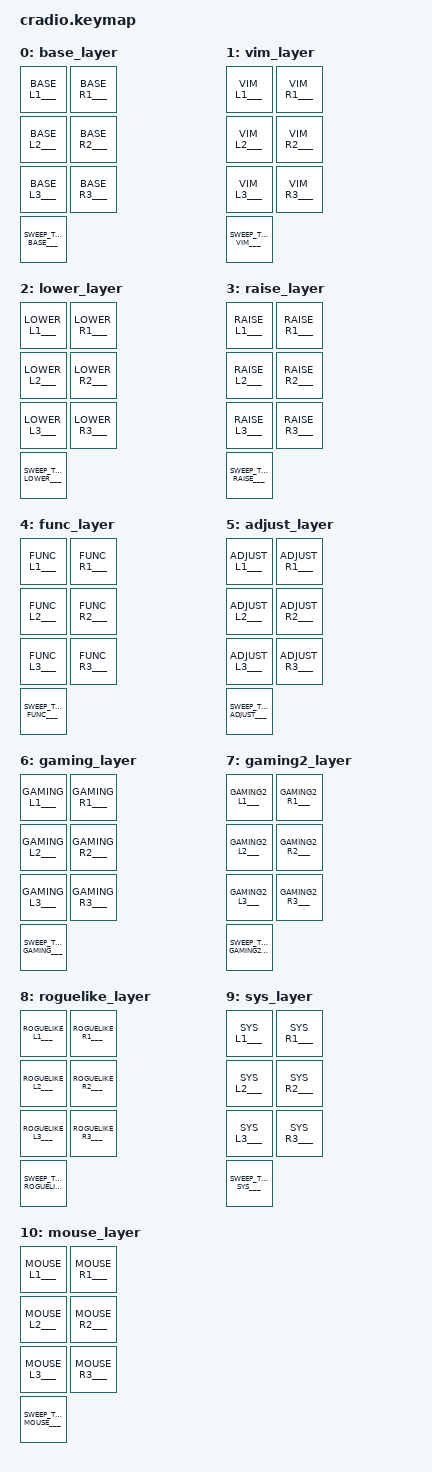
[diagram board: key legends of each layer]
// clang-format off
#include <behaviors.dtsi>
#include <dt-bindings/zmk/keys.h>
#include <dt-bindings/zmk/mouse.h>
#include "behaviors.dtsi" // before wrappers because .dtsi are fucking dumb
#include "combos.dtsi" // Shared combo definitions

/*                              34 KEY MATRIX / LAYOUT MAPPING
  ╭────────────────────┬────────────────────╮ ╭─────────────────────┬─────────────────────╮
  │  0   1   2   3   4 │  5   6   7   8   9 │ │ LT4 LT3 LT2 LT1 LT0 │ RT0 RT1 RT2 RT3 RT4 │
  │ 10  11  12  13  14 │ 15  16  17  18  19 │ │ LM4 LM3 LM2 LM1 LM0 │ RM0 RM1 RM2 RM3 RM4 │
  │ 20  21  22  23  24 │ 25  26  27  28  29 │ │ LB4 LB3 LB2 LB1 LB0 │ RB0 RB1 RB2 RB3 RB4 │
  ╰───────────╮ 30  31 │ 32  33 ╭───────────╯ ╰───────────╮ LH1 LH0 │ RH0 RH1 ╭───────────╯
              ╰────────┴────────╯                         ╰─────────┴─────────╯             */
/*            little cheater map just to fix brain farts
  ╭────────────────────┬────────────────────╮
  │  0   1   2   3   4 │  5   6   7   8   9 │
     Q   W   E   R   T    Y   U   I   O   P
  │ 10  11  12  13  14 │ 15  16  17  18  19 │
     A   S   D   F   G    H   J   K   L   ;
  │ 20  21  22  23  24 │ 25  26  27  28  29 │
     Z   X   C   V   B    N   M   ,   .   /
  ╰───────────╮ 30  31 │ 32  33 ╭───────────╯
              Bspc Space Enter Tab
              ╰────────┴────────╯ */
/ {
    combos {
        // basic functions we love
        combo_hj_caps_word {
            key-positions = <15 16>;
        };
        combo_yh_num_word {
            key-positions = <15 5>;
        };
        combo_jk_esc {
            key-positions = <16 17>;
        };
        combo_lscln_ent {
            key-positions = <18 19>;
        };
        combo_fg_tab {
            key-positions = <13 14>;
        };
        combo_cv_minus {
            key-positions = <22 23>;
        };
        combo_zx_del {
            key-positions = <20 21>;
        };
        combo_dc_assign {
            key-positions = <12 22>;
        };
        combo_gb_leader {
            key-positions = <14 24>;  // G + B
        };
        combo_as_bspc {
            key-positions = <10 11>;
        };
        combo_ui_equal {
            key-positions = <6 7>;  // U + I
        };
        combo_df_underscore {
            key-positions = <12 13>;
        };
        combo_vb_space {
            key-positions = <23 24>;  // V + B
        };
        combo_kl_sqt {
            key-positions = <17 18>;
        };
        combo_jkl_dqt {
            key-positions = <16 17 18>;
        };
        combo_kl_scln_ccs {
            key-positions = <17 18 19>;
        };
        // testing [](){} auto double and move cursor inside, right hand initiation since
        // qwerty is to heavy on left hand actions and i unintentionally made my left
        // hand symbols the more common ones as well.
        combo_nm_parens {
            key-positions = <25 26>;
        };
        combo_m_comma_braces {
            key-positions = <26 27>;
        };
        combo_comma_dot_brackets {
            key-positions = <27 28>;
        };
        combo_dot_slash_ltgt {
            key-positions = <28 29>;
        };
        // Similar concept but for quotes
        combo_jm_squotes {
            key-positions = <16 26>;
        };
        combo_k_comma_dquotes {
            key-positions = <17 27>;
        };
// =====================================================================================
// GACS but for combos and row 1 instead of homerow (row 2) this is also a test, and more
// so intended for a non-HRM layer for roguelike development, as when im not on a laptop
// it is nice to hit hjkl without the games framebuffer ignoring due to timing on firmware
// based off my old vim layers from QMK, will create that in the future, its low-pri
// =====================================================================================
        combo_qw_lgui {
            key-positions = <0 1>;
        };
        combo_we_lalt {
            key-positions = <1 2>;
        };
        combo_er_lctrl {
            key-positions = <2 3>;
        };
        combo_rt_lshift {
            key-positions = <3 4>;
        };

// =====================================================================================
        // right side
        combo_yu_rshift {
            key-positions = <5 6>;
        };
        combo_ui_rctrl {
            key-positions = <6 7>;
        };
        combo_io_ralt {
            key-positions = <7 8>;
        };
        combo_op_rgui {
            key-positions = <8 9>;
        };
// =====================================================================================
// BASE-only top row combos
// =====================================================================================
        combo_qw_noteq {
            key-positions = <0 1>;  // Q + W
        };
        combo_er_repeat {
            key-positions = <2 3>;  // E + R
        };
        combo_io_colon {
            key-positions = <7 8>;  // I + O
        };
// =====================================================================================
// Three-Finger goto layer combos
// =====================================================================================
        combo_return_to_base { // QWE on all layers to return home
            key-positions = <0 1 2>;
        };

        combo_base_to_gaming {
            key-positions = <10 11 12>; // ASD
        };

        combo_base_to_vim {
            key-positions = <25 26 27>; // NM,
        };

        combo_vim_to_base {
            key-positions = <25 26 27>; // NM, to return, qwe still works too.
        };

        combo_gaming_to_roguelike {
            key-positions = <15 16 17>; // HJK
        };

        combo_roguelike_to_gaming {
            key-positions = <15 16 17>; // HJK to go back (supposed to work even tho it will be numpad keys)
        };

        combo_gaming_to_gaming2 {
            key-positions = <5 6 7>; // YUI
        };

        combo_gaming2_to_gaming {
            key-positions = <5 6 7>; // YUI to return
        };
};

    keymap {
        compatible = "zmk,keymap";
        // base, vim, lower, raise, gaming, gaming2, roguelike, sys, mouse
        base_layer {
            bindings = <
                ___BASE_L1___ ___BASE_R1___
                ___BASE_L2___ ___BASE_R2___
                ___BASE_L3___ ___BASE_R3___
                  ___SWEEP_THUMBS_BASE___
            >;
        };

        vim_layer {
            bindings = <
                ___VIM_L1___ ___VIM_R1___
                ___VIM_L2___ ___VIM_R2___
                ___VIM_L3___ ___VIM_R3___
                  ___SWEEP_THUMBS_VIM___
            >;
        };

        lower_layer {
            bindings = <
                ___LOWER_L1___ ___LOWER_R1___
                ___LOWER_L2___ ___LOWER_R2___
                ___LOWER_L3___ ___LOWER_R3___
                  ___SWEEP_THUMBS_LOWER___
            >;
        };

        raise_layer {
            bindings = <
                ___RAISE_L1___ ___RAISE_R1___
                ___RAISE_L2___ ___RAISE_R2___
                ___RAISE_L3___ ___RAISE_R3___
                  ___SWEEP_THUMBS_RAISE___
            >;
        };

        func_layer {
            bindings = <
                ___FUNC_L1___ ___FUNC_R1___
                ___FUNC_L2___ ___FUNC_R2___
                ___FUNC_L3___ ___FUNC_R3___
                  ___SWEEP_THUMBS_FUNC___
            >;
        };

        adjust_layer {
            bindings = <
                ___ADJUST_L1___ ___ADJUST_R1___
                ___ADJUST_L2___ ___ADJUST_R2___
                ___ADJUST_L3___ ___ADJUST_R3___
                  ___SWEEP_THUMBS_ADJUST___
            >;
        };

        gaming_layer {
            bindings = <
                ___GAMING_L1___ ___GAMING_R1___
                ___GAMING_L2___ ___GAMING_R2___
                ___GAMING_L3___ ___GAMING_R3___
                  ___SWEEP_THUMBS_GAMING___
            >;
        };

        gaming2_layer {
            bindings = <
                ___GAMING2_L1___ ___GAMING2_R1___
                ___GAMING2_L2___ ___GAMING2_R2___
                ___GAMING2_L3___ ___GAMING2_R3___
                  ___SWEEP_THUMBS_GAMING2___
            >;
        };

        roguelike_layer {
            bindings = <
                ___ROGUELIKE_L1___ ___ROGUELIKE_R1___
                ___ROGUELIKE_L2___ ___ROGUELIKE_R2___
                ___ROGUELIKE_L3___ ___ROGUELIKE_R3___
                  ___SWEEP_THUMBS_ROGUELIKE___
            >;
        };

        sys_layer {
            bindings = <
                ___SYS_L1___ ___SYS_R1___
                ___SYS_L2___ ___SYS_R2___
                ___SYS_L3___ ___SYS_R3___
                  ___SWEEP_THUMBS_SYS___
            >;
        };

        mouse_layer {
            bindings = <
                ___MOUSE_L1___ ___MOUSE_R1___
                ___MOUSE_L2___ ___MOUSE_R2___
                ___MOUSE_L3___ ___MOUSE_R3___
                  ___SWEEP_THUMBS_MOUSE___
            >;
        };
    };
};
